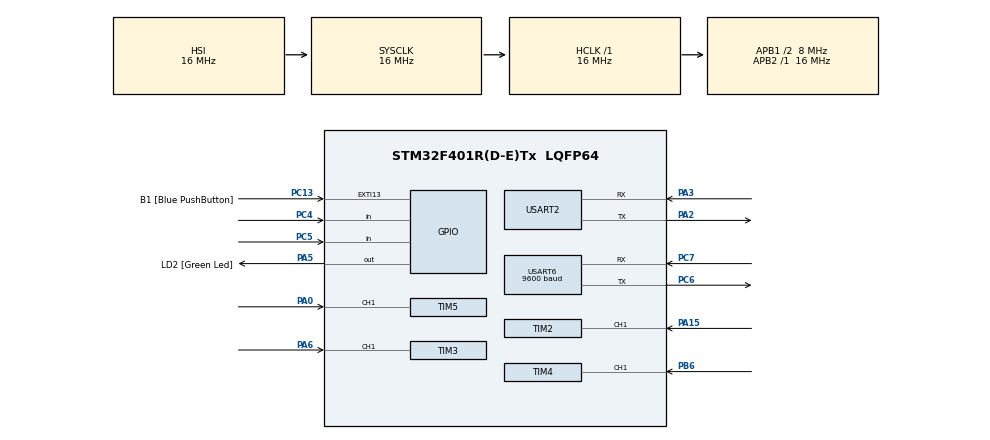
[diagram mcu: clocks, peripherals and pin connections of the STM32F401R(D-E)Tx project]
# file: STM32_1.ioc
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Mcu.Family=STM32F4
Mcu.Name=STM32F401R(D-E)Tx
Mcu.Package=LQFP64
NVIC.PriorityGroup=NVIC_PRIORITYGROUP_0
NVIC.TIM2_IRQn=true\:0\:0\:false\:false\:true\:true\:true\:true
NVIC.TIM3_IRQn=true\:0\:0\:false\:false\:true\:true\:true\:true
NVIC.TIM4_IRQn=true\:0\:0\:false\:false\:true\:true\:true\:true
NVIC.TIM5_IRQn=true\:0\:0\:false\:false\:true\:true\:true\:true
PA0-WKUP.Signal=S_TIM5_CH1
PA13.GPIO_Label=TMS
PA13.Mode=Serial_Wire
PA13.Signal=SYS_JTMS-SWDIO
PA14.GPIO_Label=TCK
PA14.Mode=Serial_Wire
PA14.Signal=SYS_JTCK-SWCLK
PA15.Signal=S_TIM2_CH1_ETR
PA2.Mode=Asynchronous
PA2.Signal=USART2_TX
PA3.Mode=Asynchronous
PA3.Signal=USART2_RX
PA5.GPIO_Label=LD2 [Green Led]
PA5.GPIO_Mode=GPIO_MODE_OUTPUT_PP
PA5.GPIO_PuPd=GPIO_NOPULL
PA5.GPIO_Speed=GPIO_SPEED_FREQ_LOW
PA5.PinState=GPIO_PIN_SET
PA5.Signal=GPIO_Output
PA6.Signal=S_TIM3_CH1
PB6.Signal=S_TIM4_CH1
PC13-ANTI_TAMP.GPIO_Label=B1 [Blue PushButton]
PC13-ANTI_TAMP.GPIO_ModeDefaultEXTI=GPIO_MODE_IT_FALLING
PC13-ANTI_TAMP.GPIO_PuPd=GPIO_NOPULL
PC13-ANTI_TAMP.Signal=GPXTI13
PC4.Signal=GPIO_Input
PC5.Signal=GPIO_Input
PC6.Mode=Asynchronous
PC6.Signal=USART6_TX
PC7.Mode=Asynchronous
PC7.Signal=USART6_RX
ProjectManager.HeapSize=0x200
ProjectManager.StackSize=0x400
ProjectManager.TargetToolchain=EWARM V8.50
RCC.48MHZClocksFreq_Value=18285714.285714287
RCC.AHBFreq_Value=16000000
RCC.APB1CLKDivider=RCC_HCLK_DIV2
RCC.APB1Freq_Value=8000000
RCC.APB1TimFreq_Value=16000000
RCC.APB2Freq_Value=16000000
RCC.APB2TimFreq_Value=16000000
RCC.CortexFreq_Value=16000000
RCC.HCLKFreq_Value=16000000
RCC.HSE_VALUE=16000000
RCC.HSI_VALUE=16000000
RCC.LSE_VALUE=32768
RCC.PLLM=8
RCC.PLLN=64
RCC.PLLQ=7
RCC.SYSCLKFreq_VALUE=16000000
RCC.VCOOutputFreq_Value=128000000
SH.S_TIM2_CH1_ETR.0=TIM2_CH1,PWM_Input_1
SH.S_TIM3_CH1.0=TIM3_CH1,PWM_Input_1
SH.S_TIM4_CH1.0=TIM4_CH1,PWM_Input_1
SH.S_TIM5_CH1.0=TIM5_CH1,PWM_Input_1
USART2.VirtualMode=VM_ASYNC
USART6.BaudRate=9600
USART6.VirtualMode=VM_ASYNC
VP_TIM2_VS_ClockSourceINT.Mode=Internal
VP_TIM3_VS_ClockSourceINT.Mode=Internal
VP_TIM4_VS_ClockSourceINT.Mode=Internal
VP_TIM5_VS_ClockSourceINT.Mode=Internal
board=NUCLEO-F401RE

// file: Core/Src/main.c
/* USER CODE BEGIN Header */
/**
  ******************************************************************************
  * @file           : main.c
  * @brief          : Main program body
  ******************************************************************************
  * @attention
  *
  * Copyright (c) 2024 STMicroelectronics.
  * All rights reserved.
  *
  * This software is licensed under terms that can be found in the LICENSE file
  * in the root directory of this software component.
  * If no LICENSE file comes with this software, it is provided AS-IS.
  *
  ******************************************************************************
  */
/* USER CODE END Header */
#include "main.h"
#include "tim.h"
#include "usart.h"
#include "gpio.h"

/* USER CODE BEGIN PD */
#define STD_ON        		(0x01U)
#define STD_OFF       		(0x00U)
#define LED_ON 						HAL_GPIO_WritePin(GPIOA, GPIO_PIN_5, STD_ON);
#define LED_OFF						HAL_GPIO_WritePin(GPIOA, GPIO_PIN_5, STD_OFF);
/* USER CODE END PD */

void SystemClock_Config(void);

int main(void)
{

  /* MCU Configuration--------------------------------------------------------*/

  /* Reset of all peripherals, Initializes the Flash interface and the Systick. */
  HAL_Init();

  /* Configure the system clock */
  SystemClock_Config();

  /* Initialize all configured peripherals */
  MX_GPIO_Init();
  MX_TIM2_Init();
  MX_TIM3_Init();
  MX_TIM4_Init();
  MX_TIM5_Init();
  MX_USART2_UART_Init();
  MX_USART6_UART_Init();

  /* Infinite loop */
  /* USER CODE BEGIN WHILE */
  while (1)
  {
    HAL_GPIO_WritePin(LD2_GPIO_Port, LD2_Pin, GPIO_PIN_SET);
    LED_ON

    /* USER CODE END WHILE */

  }
}

void SystemClock_Config(void)
{
  RCC_OscInitTypeDef RCC_OscInitStruct = {0};
  RCC_ClkInitTypeDef RCC_ClkInitStruct = {0};

  /** Configure the main internal regulator output voltage
  */
  __HAL_RCC_PWR_CLK_ENABLE();
  __HAL_PWR_VOLTAGESCALING_CONFIG(PWR_REGULATOR_VOLTAGE_SCALE2);

  /** Initializes the RCC Oscillators according to the specified parameters
  * in the RCC_OscInitTypeDef structure.
  */
  RCC_OscInitStruct.OscillatorType = RCC_OSCILLATORTYPE_HSI;
  RCC_OscInitStruct.HSIState = RCC_HSI_ON;
  RCC_OscInitStruct.HSICalibrationValue = RCC_HSICALIBRATION_DEFAULT;
  RCC_OscInitStruct.PLL.PLLState = RCC_PLL_NONE;
  if (HAL_RCC_OscConfig(&RCC_OscInitStruct) != HAL_OK)
  {
    Error_Handler();
  }

  /** Initializes the CPU, AHB and APB buses clocks
  */
  RCC_ClkInitStruct.ClockType = RCC_CLOCKTYPE_HCLK|RCC_CLOCKTYPE_SYSCLK
                              |RCC_CLOCKTYPE_PCLK1|RCC_CLOCKTYPE_PCLK2;
  RCC_ClkInitStruct.SYSCLKSource = RCC_SYSCLKSOURCE_HSI;
  RCC_ClkInitStruct.AHBCLKDivider = RCC_SYSCLK_DIV1;
  RCC_ClkInitStruct.APB1CLKDivider = RCC_HCLK_DIV2;
  RCC_ClkInitStruct.APB2CLKDivider = RCC_HCLK_DIV1;

  if (HAL_RCC_ClockConfig(&RCC_ClkInitStruct, FLASH_LATENCY_0) != HAL_OK)
  {
    Error_Handler();
  }
}

void Error_Handler(void)
{
  /* USER CODE BEGIN Error_Handler_Debug */
  /* User can add his own implementation to report the HAL error return state */
  __disable_irq();
  while (1)
  {
    LED_ON
  }
  /* USER CODE END Error_Handler_Debug */
}
